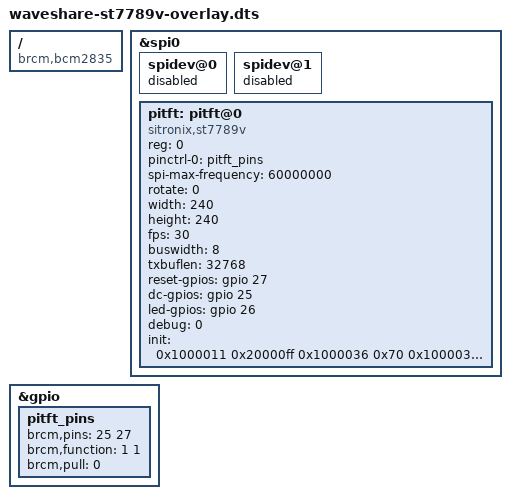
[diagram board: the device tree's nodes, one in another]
/*
 * Device Tree overlay for Adafruit Mini PiTFT 1.3" and 1.5" 240x240 Display
 *
 */

/dts-v1/;
/plugin/;

/ {
        compatible = "brcm,bcm2835", "brcm,bcm2708", "brcm,bcm2709";

        fragment@0 {
                target = <&spi0>;
                __overlay__ {
                        status = "okay";

                        spidev@0{
                                status = "disabled";
                        };

                        spidev@1{
                                status = "disabled";
                        };
                };
        };

        fragment@1 {
                target = <&gpio>;
                __overlay__ {
                        pitft_pins: pitft_pins {
                                brcm,pins = <25 27>;
                                brcm,function = <1 1>; /* out */
                                brcm,pull = <0>; /* none */
                        };
                };
        };

        fragment@2 {
                target = <&spi0>;
                __overlay__ {
                        /* needed to avoid dtc warning */
                        #address-cells = <1>;
                        #size-cells = <0>;

                        pitft: pitft@0{
                		compatible = "sitronix,st7789v";
                                reg = <0>;
                                pinctrl-names = "default";
                                pinctrl-0 = <&pitft_pins>;
                                spi-max-frequency = <60000000>;
                                rotate = <0>;
                                width = <240>;
                                height = <240>;
				                fps = <30>;
                                buswidth = <8>;
				                txbuflen = <32768>;
                                reset-gpios = <&gpio 27 0>;
				                dc-gpios = <&gpio 25 0>;
                                led-gpios = <&gpio 26 0>;
                                debug = <0>;
					
				init = <0x1000011
					0x20000ff
					0x1000036 0x70
					0x100003a 0x05
					0x10000b2 0x0c 0x0c 0x00 0x33 0x33
					0x10000b7 0x35
					0x10000bb 0x1a
					0x10000c0 0x2c
					0x10000c2 0x01
					0x10000c3 0x0b
					0x10000c4 0x20
					0x10000c6 0x0f
					0x10000d0 0xa4 0xa1
					0x1000021 
					0x10000e0 0x00 0x19 0x1E 0x0A 0x09 0x15 0x3D 0x44 0x51 0x12 0x03 0x00 0x3F 0x3F				
					0x10000e1 0x00 0x18 0x1E 0x0A 0x09 0x25 0x3F 0x43 0x52 0x33 0x03 0x00 0x3F 0x3F
					0x1000029>;
                        };
                };
        };


        __overrides__ {
                speed =   <&pitft>,"spi-max-frequency:0";
                rotate =  <&pitft>,"rotate:0";
                width =   <&pitft>,"width:0";
                height =  <&pitft>,"height:0";
                fps =     <&pitft>,"fps:0";
                debug =   <&pitft>,"debug:0";
        };
};
